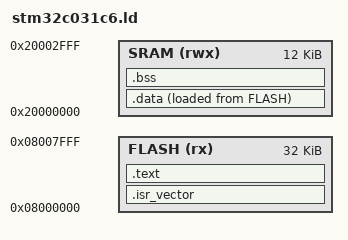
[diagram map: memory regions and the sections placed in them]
ENTRY(Reset_Handler)

MEMORY
{
  FLASH (rx)  : ORIGIN = 0x08000000, LENGTH = 32K
  SRAM   (rwx) : ORIGIN = 0x20000000, LENGTH = 12K
}

top_of_stack = ORIGIN(SRAM) + LENGTH(SRAM);

SECTIONS
{

.isr_vector :
  {
    KEEP(*(.isr_vector));
    . = ALIGN(4);
  }> FLASH

.text :
  {
    *(.text)
    *(.text.*)
    *(.rodata)
    *(.rodata.*)
    . = ALIGN(4);
    _etext = .;
  }> FLASH

_la_data = LOADADDR(.data);
  .data :
  {
    _sdata = .;
    *(.data)
    *(.data.*)
    . = ALIGN(4);
    _edata = .;
  }> SRAM AT> FLASH

.bss :
  {
    _sbss = .;
    __bss_start__ = _sbss;
    *(.bss)
    *(.bss.*)
    . = ALIGN(4);
    _ebss = .;
    __bss_end__ = _ebss;
     . = ALIGN(4);
    end = .;
    __end__ = .;
  }> SRAM


}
